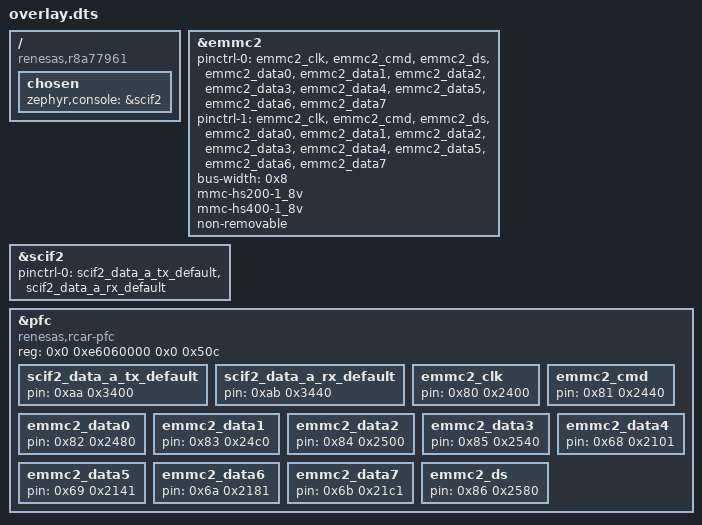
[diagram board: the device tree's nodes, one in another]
/ {
	compatible = "renesas,r8a77961";
	chosen {
		zephyr,console = &scif2;
	};
};
&emmc2{
	pinctrl-0 = < &emmc2_clk &emmc2_cmd &emmc2_ds &emmc2_data0 &emmc2_data1 &emmc2_data2 &emmc2_data3 &emmc2_data4 &emmc2_data5 &emmc2_data6 &emmc2_data7 >;
	pinctrl-1 = < &emmc2_clk &emmc2_cmd &emmc2_ds &emmc2_data0 &emmc2_data1 &emmc2_data2 &emmc2_data3 &emmc2_data4 &emmc2_data5 &emmc2_data6 &emmc2_data7 >;
	pinctrl-names = "default", "uhs";
	bus-width = < 0x8 >;
	mmc-hs200-1_8v;
	mmc-hs400-1_8v;
	non-removable;
};
&scif2{
	status = "okay";
	pinctrl-0 = < &scif2_data_a_tx_default &scif2_data_a_rx_default >;
	pinctrl-names = "default";
};
&pfc{
	compatible = "renesas,rcar-pfc";
	reg = < 0x0 0xe6060000 0x0 0x50c >;
	scif2_data_a_tx_default: scif2_data_a_tx_default {
		pin = < 0xaa 0x3400 >;
	};
	scif2_data_a_rx_default: scif2_data_a_rx_default {
		pin = < 0xab 0x3440 >;
	};
	emmc2_clk: emmc2_clk {
		pin = < 0x80 0x2400 >;
	};
	emmc2_cmd: emmc2_cmd {
		pin = < 0x81 0x2440 >;
	};
	emmc2_data0: emmc2_data0 {
		pin = < 0x82 0x2480 >;
	};
	emmc2_data1: emmc2_data1 {
		pin = < 0x83 0x24c0 >;
	};
	emmc2_data2: emmc2_data2 {
		pin = < 0x84 0x2500 >;
	};
	emmc2_data3: emmc2_data3 {
		pin = < 0x85 0x2540 >;
	};
	emmc2_data4: emmc2_data4 {
		pin = < 0x68 0x2101 >;
	};
	emmc2_data5: emmc2_data5 {
		pin = < 0x69 0x2141 >;
	};
	emmc2_data6: emmc2_data6 {
		pin = < 0x6a 0x2181 >;
	};
	emmc2_data7: emmc2_data7 {
		pin = < 0x6b 0x21c1 >;
	};
	emmc2_ds: emmc2_ds {
		pin = < 0x86 0x2580 >;
	};
};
